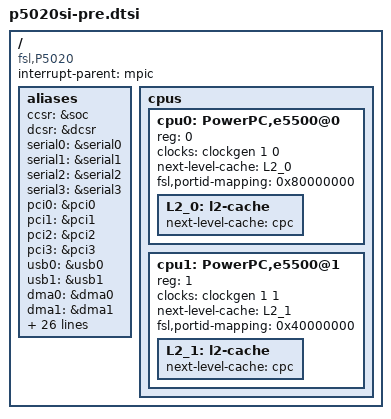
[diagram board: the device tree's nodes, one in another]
/dts-v1/;
/include/ "e5500_power_isa.dtsi"
/ {
	compatible = "fsl,P5020";
	#address-cells = <2>;
	#size-cells = <2>;
	interrupt-parent = <&mpic>;
	aliases {
		ccsr = &soc;
		dcsr = &dcsr;
		serial0 = &serial0;
		serial1 = &serial1;
		serial2 = &serial2;
		serial3 = &serial3;
		pci0 = &pci0;
		pci1 = &pci1;
		pci2 = &pci2;
		pci3 = &pci3;
		usb0 = &usb0;
		usb1 = &usb1;
		dma0 = &dma0;
		dma1 = &dma1;
		sdhc = &sdhc;
		msi0 = &msi0;
		msi1 = &msi1;
		msi2 = &msi2;
		crypto = &crypto;
		sec_jr0 = &sec_jr0;
		sec_jr1 = &sec_jr1;
		sec_jr2 = &sec_jr2;
		sec_jr3 = &sec_jr3;
		rtic_a = &rtic_a;
		rtic_b = &rtic_b;
		rtic_c = &rtic_c;
		rtic_d = &rtic_d;
		sec_mon = &sec_mon;
		raideng = &raideng;
		raideng_jr0 = &raideng_jr0;
		raideng_jr1 = &raideng_jr1;
		raideng_jr2 = &raideng_jr2;
		raideng_jr3 = &raideng_jr3;
		fman0 = &fman0;
		ethernet0 = &enet0;
		ethernet1 = &enet1;
		ethernet2 = &enet2;
		ethernet3 = &enet3;
		ethernet4 = &enet4;
		ethernet5 = &enet5;
	};
	cpus {
		#address-cells = <1>;
		#size-cells = <0>;
		cpu0: PowerPC,e5500@0 {
			device_type = "cpu";
			reg = <0>;
			clocks = <&clockgen 1 0>;
			next-level-cache = <&L2_0>;
			fsl,portid-mapping = <0x80000000>;
			L2_0: l2-cache {
				next-level-cache = <&cpc>;
			};
		};
		cpu1: PowerPC,e5500@1 {
			device_type = "cpu";
			reg = <1>;
			clocks = <&clockgen 1 1>;
			next-level-cache = <&L2_1>;
			fsl,portid-mapping = <0x40000000>;
			L2_1: l2-cache {
				next-level-cache = <&cpc>;
			};
		};
	};
};
